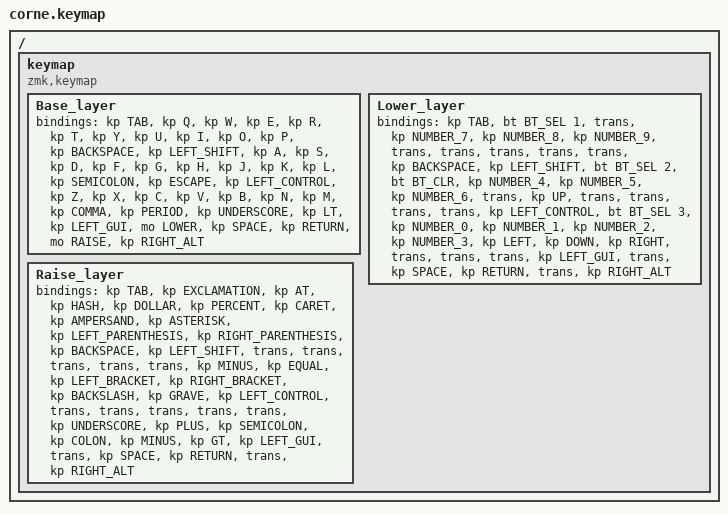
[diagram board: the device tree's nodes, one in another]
#include <behaviors.dtsi>
#include <dt-bindings/zmk/keys.h>
#include <dt-bindings/zmk/bt.h>

#define BASE 0
#define LOWER 1
#define RAISE 2

/ {
  keymap {
    compatible = "zmk,keymap";

    Base_layer {
      bindings = <
        &kp TAB &kp Q &kp W &kp E &kp R &kp T &kp Y &kp U &kp I &kp O &kp P &kp BACKSPACE &kp LEFT_SHIFT &kp A &kp S &kp D &kp F &kp G &kp H &kp J &kp K &kp L &kp SEMICOLON &kp ESCAPE &kp LEFT_CONTROL &kp Z &kp X &kp C &kp V &kp B &kp N &kp M &kp COMMA &kp PERIOD &kp UNDERSCORE &kp LT &kp LEFT_GUI &mo LOWER &kp SPACE &kp RETURN &mo RAISE &kp RIGHT_ALT 
      >;
    };

    Lower_layer {
      bindings = <
        &kp TAB &bt BT_SEL 1 &trans &kp NUMBER_7 &kp NUMBER_8 &kp NUMBER_9 &trans &trans &trans &trans &trans &kp BACKSPACE &kp LEFT_SHIFT &bt BT_SEL 2 &bt BT_CLR &kp NUMBER_4 &kp NUMBER_5 &kp NUMBER_6 &trans &kp UP &trans &trans &trans &trans &kp LEFT_CONTROL &bt BT_SEL 3 &kp NUMBER_0 &kp NUMBER_1 &kp NUMBER_2 &kp NUMBER_3 &kp LEFT &kp DOWN &kp RIGHT &trans &trans &trans &kp LEFT_GUI &trans &kp SPACE &kp RETURN &trans &kp RIGHT_ALT 
      >;
    };

    Raise_layer {
      bindings = <
        &kp TAB &kp EXCLAMATION &kp AT &kp HASH &kp DOLLAR &kp PERCENT &kp CARET &kp AMPERSAND &kp ASTERISK &kp LEFT_PARENTHESIS &kp RIGHT_PARENTHESIS &kp BACKSPACE &kp LEFT_SHIFT &trans &trans &trans &trans &trans &kp MINUS &kp EQUAL &kp LEFT_BRACKET &kp RIGHT_BRACKET &kp BACKSLASH &kp GRAVE &kp LEFT_CONTROL &trans &trans &trans &trans &trans &kp UNDERSCORE &kp PLUS &kp SEMICOLON &kp COLON &kp MINUS &kp GT &kp LEFT_GUI &trans &kp SPACE &kp RETURN &trans &kp RIGHT_ALT 
      >;
    };

  };
};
